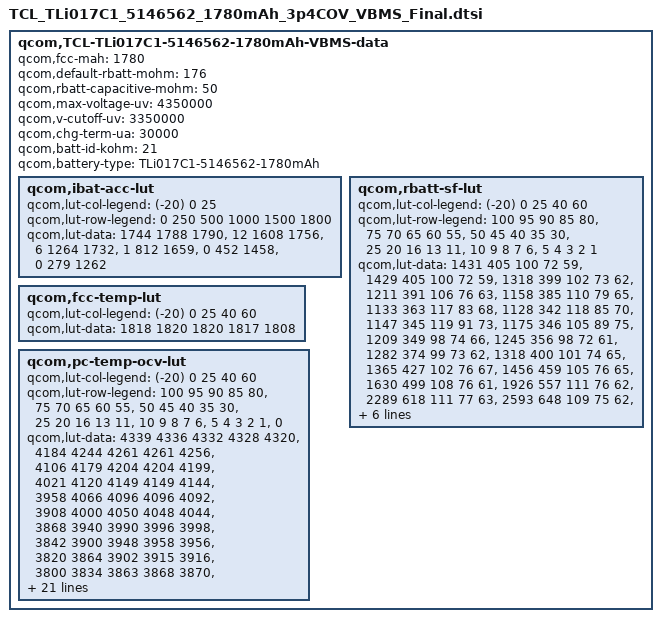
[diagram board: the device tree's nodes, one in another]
 qcom,TCL-TLi017C1-5146562-1780mAh-VBMS-data {
	qcom,fcc-mah = <1780>;
	qcom,default-rbatt-mohm = <176>;
	qcom,rbatt-capacitive-mohm = <50>;
	qcom,max-voltage-uv = <4350000>;
	qcom,v-cutoff-uv = <3350000>;
	qcom,chg-term-ua = <30000>;
	qcom,batt-id-kohm = <21>;
	qcom,battery-type = "TLi017C1-5146562-1780mAh";

	qcom,ibat-acc-lut {
		qcom,lut-col-legend = <(-20) 0 25>;
		qcom,lut-row-legend = <0 250 500 1000 1500 1800>;
		qcom,lut-data = <1744 1788 1790>,
				<12 1608 1756>,
				<6 1264 1732>,
				<1 812 1659>,
				<0 452 1458>,
				<0 279 1262>;
	};

	qcom,rbatt-sf-lut {
		qcom,lut-col-legend = <(-20) 0 25 40 60>;
		qcom,lut-row-legend = <100 95 90 85 80>,
				<75 70 65 60 55>,
				<50 45 40 35 30>,
				<25 20 16 13 11>,
				<10 9 8 7 6>,
				<5 4 3 2 1>;
		qcom,lut-data = <1431 405 100 72 59>,
				<1429 405 100 72 59>,
				<1318 399 102 73 62>,
				<1211 391 106 76 63>,
				<1158 385 110 79 65>,
				<1133 363 117 83 68>,
				<1128 342 118 85 70>,
				<1147 345 119 91 73>,
				<1175 346 105 89 75>,
				<1209 349 98 74 66>,
				<1245 356 98 72 61>,
				<1282 374 99 73 62>,
				<1318 400 101 74 65>,
				<1365 427 102 76 67>,
				<1456 459 105 76 65>,
				<1630 499 108 76 61>,
				<1926 557 111 76 62>,
				<2289 618 111 77 63>,
				<2593 648 109 75 62>,
				<2771 645 112 76 63>,
				<3030 668 115 77 65>,
				<3343 695 119 81 67>,
				<3723 727 125 83 69>,
				<4199 760 131 87 70>,
				<4797 801 138 89 72>,
				<5598 843 142 86 67>,
				<6714 895 144 85 67>,
				<8386 966 155 89 68>,
				<11302 1123 176 97 74>,
				<18860 2219 301 162 114>;
	};

	qcom,fcc-temp-lut {
		qcom,lut-col-legend = <(-20) 0 25 40 60>;
		qcom,lut-data = <1818 1820 1820 1817 1808>;
	};

	qcom,pc-temp-ocv-lut {
		qcom,lut-col-legend = <(-20) 0 25 40 60>;
		qcom,lut-row-legend = <100 95 90 85 80>,
				<75 70 65 60 55>,
				<50 45 40 35 30>,
				<25 20 16 13 11>,
				<10 9 8 7 6>,
				<5 4 3 2 1>,
				<0>;
		qcom,lut-data = <4339 4336 4332 4328 4320>,
				<4184 4244 4261 4261 4256>,
				<4106 4179 4204 4204 4199>,
				<4021 4120 4149 4149 4144>,
				<3958 4066 4096 4096 4092>,
				<3908 4000 4050 4048 4044>,
				<3868 3940 3990 3996 3998>,
				<3842 3900 3948 3958 3956>,
				<3820 3864 3902 3915 3916>,
				<3800 3834 3863 3868 3870>,
				<3780 3808 3834 3836 3836>,
				<3759 3790 3810 3812 3813>,
				<3738 3774 3791 3792 3793>,
				<3716 3757 3775 3776 3776>,
				<3691 3740 3763 3762 3758>,
				<3664 3724 3751 3748 3736>,
				<3632 3709 3733 3729 3716>,
				<3600 3696 3706 3704 3691>,
				<3574 3684 3688 3682 3670>,
				<3552 3673 3684 3678 3666>,
				<3538 3666 3682 3676 3665>,
				<3522 3656 3680 3675 3664>,
				<3504 3644 3678 3673 3662>,
				<3484 3628 3674 3670 3659>,
				<3460 3607 3666 3662 3650>,
				<3432 3580 3642 3638 3620>,
				<3398 3546 3598 3592 3572>,
				<3358 3500 3535 3528 3508>,
				<3304 3426 3445 3440 3420>,
				<3218 3298 3308 3306 3288>,
				<3000 3000 3000 3000 3000>;
	};
};
